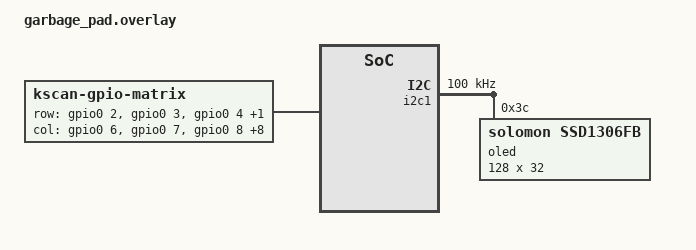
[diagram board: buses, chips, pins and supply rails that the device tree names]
#include <dt-bindings/pinctrl/rpi-pico-rp2040-pinctrl.h>
#include <dt-bindings/i2c/i2c.h>
#include <dt-bindings/zmk/matrix_transform.h>

/ {
	chosen {
		zmk,kscan= &kscan0;
		zephyr,display = &oled;
	};

	kscan0: kscan_0 {
		compatible = "zmk,kscan-gpio-matrix";
		label = "KSCAN";
		diode-direction = "col2row";

	row-gpios
		= <&gpio0 2 (GPIO_ACTIVE_HIGH | GPIO_PULL_DOWN)>
		, <&gpio0 3 (GPIO_ACTIVE_HIGH | GPIO_PULL_DOWN)>
		, <&gpio0 4 (GPIO_ACTIVE_HIGH | GPIO_PULL_DOWN)>
		, <&gpio0 5 (GPIO_ACTIVE_HIGH | GPIO_PULL_DOWN)>
		;

	col-gpios
		= <&gpio0 6 GPIO_ACTIVE_HIGH>
		, <&gpio0 7 GPIO_ACTIVE_HIGH>
		, <&gpio0 8 GPIO_ACTIVE_HIGH>
		, <&gpio0 9 GPIO_ACTIVE_HIGH>
		, <&gpio0 10 GPIO_ACTIVE_HIGH>
		, <&gpio0 11 GPIO_ACTIVE_HIGH>
		, <&gpio0 12 GPIO_ACTIVE_HIGH>
		, <&gpio0 13 GPIO_ACTIVE_HIGH>
		, <&gpio0 14 GPIO_ACTIVE_HIGH>
		, <&gpio0 15 GPIO_ACTIVE_HIGH>
		, <&gpio0 16 GPIO_ACTIVE_HIGH>
		;
	};
};

&pinctrl {
	i2c1_custom: i2c1_custom {
		group1 {
			pinmux = <I2C1_SDA_P26>, <I2C1_SCL_P27>;
			input-enable;
			input-schmitt-enable;
			bias-pull-up;
		};
	};
};

&i2c1 {
	status = "okay";
	pinctrl-0 = <&i2c1_custom>;
	pinctrl-names = "default";
	clock-frequency = <I2C_BITRATE_STANDARD>;

	oled: ssd1306@3c {
		compatible = "solomon,ssd1306fb";
		reg = <0x3c>;
		width = <128>;
		height = <32>;
		segment-offset = <0>;
		page-offset = <0>;
		display-offset = <0>;
		multiplex-ratio = <31>;
		segment-remap;
		prechargep = <0x22>;

	};
};
